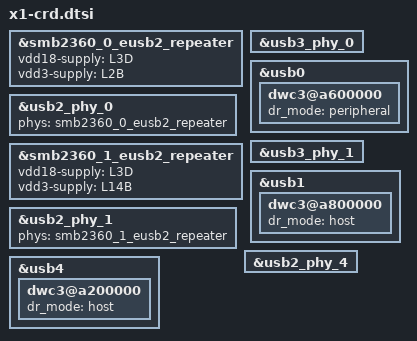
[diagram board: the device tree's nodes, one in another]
// SPDX-License-Identifier: BSD-3-Clause
/*
 * Copyright (c) Qualcomm Technologies, Inc. and/or its subsidiaries.
 */

&smb2360_0_eusb2_repeater {
	vdd18-supply = <&L3D>;
	vdd3-supply = <&L2B>;
};

&usb2_phy_0 {
	phys = <&smb2360_0_eusb2_repeater>;
	status = "okay";
};

&usb3_phy_0 {
	status = "okay";
};

&usb0 {
	status = "okay";
	dwc3@a600000 {
		dr_mode = "peripheral";
	};
};

&smb2360_1_eusb2_repeater {
	vdd18-supply = <&L3D>;
	vdd3-supply = <&L14B>;
};

&usb2_phy_1 {
	phys = <&smb2360_1_eusb2_repeater>;
	status = "okay";
};

&usb3_phy_1 {
	status = "okay";
};

&usb1 {
	status = "okay";
	dwc3@a800000 {
		dr_mode = "host";
	};
};

&usb2_phy_4 {
	status = "okay";
};

&usb4 {
	status = "okay";
	dwc3@a200000 {
		dr_mode = "host";
	};
};
